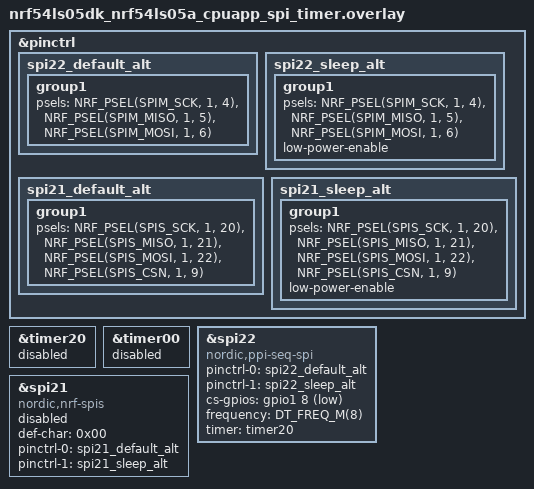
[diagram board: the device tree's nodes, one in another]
/*
 * Copyright (c) 2026 Nordic Semiconductor ASA
 *
 * SPDX-License-Identifier: LicenseRef-Nordic-5-Clause
 */

/* Test requires loopbacks:
 * - between P1.04 and P1.20
 * - between P1.05 and P1.21
 * - between P1.06 and P1.22
 * - between P1.08 and P1.09
 */

&pinctrl {
	spi22_default_alt: spi22_default_alt {
		group1 {
			psels = <NRF_PSEL(SPIM_SCK, 1, 4)>,
				<NRF_PSEL(SPIM_MISO, 1, 5)>,
				<NRF_PSEL(SPIM_MOSI, 1, 6)>;
		};
	};

	spi22_sleep_alt: spi22_sleep_alt {
		group1 {
			psels = <NRF_PSEL(SPIM_SCK, 1, 4)>,
				<NRF_PSEL(SPIM_MISO, 1, 5)>,
				<NRF_PSEL(SPIM_MOSI, 1, 6)>;
			low-power-enable;
		};
	};

	spi21_default_alt: spi21_default_alt {
		group1 {
			psels = <NRF_PSEL(SPIS_SCK, 1, 20)>,
				<NRF_PSEL(SPIS_MISO, 1, 21)>,
				<NRF_PSEL(SPIS_MOSI, 1, 22)>,
				<NRF_PSEL(SPIS_CSN, 1, 9)>;
		};
	};

	spi21_sleep_alt: spi21_sleep_alt {
		group1 {
			psels = <NRF_PSEL(SPIS_SCK, 1, 20)>,
				<NRF_PSEL(SPIS_MISO, 1, 21)>,
				<NRF_PSEL(SPIS_MOSI, 1, 22)>,
				<NRF_PSEL(SPIS_CSN, 1, 9)>;
			low-power-enable;
		};
	};
};

/* Used as trigger by the PPI sequencer. */
&timer20 {
	status = "reserved";
};

test_timer: &timer00 {
	status = "reserved";
};

dut: &spi22 {
	compatible = "nordic,ppi-seq-spi";
	status = "okay";
	pinctrl-0 = <&spi22_default_alt>;
	pinctrl-1 = <&spi22_sleep_alt>;
	pinctrl-names = "default", "sleep";
	cs-gpios = <&gpio1 8 GPIO_ACTIVE_LOW>;
	frequency = <DT_FREQ_M(8)>;
	timer = <&timer20>;
};

tester: &spi21 {
	compatible = "nordic,nrf-spis";
	status = "reserved";
	def-char = <0x00>;
	pinctrl-0 = <&spi21_default_alt>;
	pinctrl-1 = <&spi21_sleep_alt>;
	pinctrl-names = "default", "sleep";
	/delete-property/ rx-delay-supported;
	/delete-property/ rx-delay;
};
